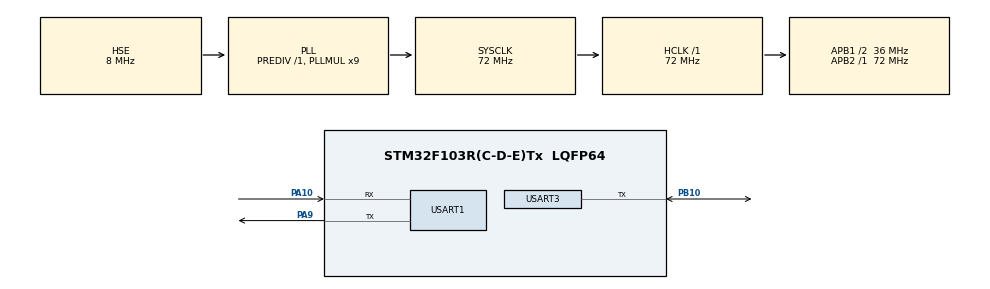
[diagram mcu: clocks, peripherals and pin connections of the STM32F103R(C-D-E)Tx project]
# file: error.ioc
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Mcu.Family=STM32F1
Mcu.Name=STM32F103R(C-D-E)Tx
Mcu.Package=LQFP64
NVIC.PriorityGroup=NVIC_PRIORITYGROUP_4
PA10.Mode=Asynchronous
PA10.Signal=USART1_RX
PA13.Mode=Serial_Wire
PA13.Signal=SYS_JTMS-SWDIO
PA14.Mode=Serial_Wire
PA14.Signal=SYS_JTCK-SWCLK
PA9.Mode=Asynchronous
PA9.Signal=USART1_TX
PB10.Mode=Half_duplex(single_wire_mode)
PB10.Signal=USART3_TX
PD0-OSC_IN.Mode=HSE-External-Oscillator
PD0-OSC_IN.Signal=RCC_OSC_IN
PD1-OSC_OUT.Mode=HSE-External-Oscillator
PD1-OSC_OUT.Signal=RCC_OSC_OUT
ProjectManager.HeapSize=0x200
ProjectManager.StackSize=0x400
ProjectManager.TargetToolchain=CMake
RCC.AHBFreq_Value=72000000
RCC.APB1CLKDivider=RCC_HCLK_DIV2
RCC.APB1Freq_Value=36000000
RCC.APB1TimFreq_Value=72000000
RCC.APB2Freq_Value=72000000
RCC.APB2TimFreq_Value=72000000
RCC.HCLKFreq_Value=72000000
RCC.PLLMUL=RCC_PLL_MUL9
RCC.PLLSourceVirtual=RCC_PLLSOURCE_HSE
RCC.SYSCLKFreq_VALUE=72000000
RCC.SYSCLKSource=RCC_SYSCLKSOURCE_PLLCLK
RCC.USBFreq_Value=72000000
USART1.VirtualMode=VM_ASYNC
USART3.VirtualMode=VM_ASYNC
board=custom

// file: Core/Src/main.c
/* USER CODE BEGIN Header */
/**
  ******************************************************************************
  * @file           : main.c
  * @brief          : Main program body
  ******************************************************************************
  * @attention
  *
  * Copyright (c) 2026 STMicroelectronics.
  * All rights reserved.
  *
  * This software is licensed under terms that can be found in the LICENSE file
  * in the root directory of this software component.
  * If no LICENSE file comes with this software, it is provided AS-IS.
  *
  ******************************************************************************
  */
/* USER CODE END Header */
#include "main.h"

/* USER CODE BEGIN Includes */
#include <stdio.h>          /* printf / getchar 的声明 */
#include "servo_app.h"      /* 舵机应用层：ServoApp_xxx */
/* USER CODE END Includes */

/* USER CODE BEGIN PD */
/* 演示开关：0 = 不动作，1 = 上电后每 2 秒在 45°/225° 之间来回 */
#define SERVO_DEMO_ENABLE 0
/* USER CODE END PD */

UART_HandleTypeDef huart1;
UART_HandleTypeDef huart3;

void SystemClock_Config(void);
static void MX_GPIO_Init(void);
static void MX_USART1_UART_Init(void);
static void MX_USART3_UART_Init(void);

/* USER CODE BEGIN 0 */
/*
 * printf 的底层出口。
 * newlib 的 printf 最终会调用 syscalls.c 里的 _write()，
 * 而 _write() 是 weak 的，它逐字节调用 __io_putchar()。
 * 这个函数不定义的话链接不报错，但运行时跳到 0 地址 -> HardFault。
 */
int __io_putchar(int ch)
{
  HAL_UART_Transmit(&huart1, (uint8_t *)&ch, 1U, 100U);
  return ch;
}

/* 同理，scanf / getchar 的入口；这里用不到，返回 -1 防止卡死 */
int __io_getchar(void)
{
  return -1;
}
/* USER CODE END 0 */

int main(void)
{

  /* MCU Configuration--------------------------------------------------------*/

  /* Reset of all peripherals, Initializes the Flash interface and the Systick. */
  HAL_Init();

  /* Configure the system clock */
  SystemClock_Config();

  /* Initialize all configured peripherals */
  MX_GPIO_Init();
  MX_USART1_UART_Init();
  MX_USART3_UART_Init();
  /* USER CODE BEGIN 2 */
  printf("\r\n==== bus servo init ====\r\n");

  ServoApp_Init(&huart3);                  /* 绑定串口，四颗摆到行程中点 */
  printf("init status : %d\r\n", (int)ServoApp_LastStatus());

  uint8_t mask = ServoApp_ScanPresent();   /* 0x0F = ID 1~4 都在线 */
  printf("present mask: 0x%02X\r\n", mask);
  /* USER CODE END 2 */

  /* Infinite loop */
  /* USER CODE BEGIN WHILE */
  uint32_t tick = HAL_GetTick();           /* 定时基准，只在进入循环前取一次 */

  while (1)
  {
    /* USER CODE END WHILE */

    /* USER CODE BEGIN 3 */
    /* 10ms 周期任务：tick 用累加而不是重新取时间，周期才不漂 */
    if ((HAL_GetTick() - tick) >= SERVO_TASK_PERIOD_MS)
    {
      tick += SERVO_TASK_PERIOD_MS;
      ServoApp_Task();
    }

#if SERVO_DEMO_ENABLE
    /* 演示：每 2 秒在 45° 和 225° 之间来回 */
    static uint32_t last_demo = 0;
    static int16_t  demo_deg  = 45;
    if ((HAL_GetTick() - last_demo) > 2000U)
    {
      last_demo = HAL_GetTick();
      ServoApp_SetAll((int16_t[]){demo_deg, demo_deg, demo_deg, demo_deg});
      demo_deg = (demo_deg == 45) ? 225 : 45;
    }
#endif
  }
  /* USER CODE END 3 */
}

void SystemClock_Config(void)
{
  RCC_OscInitTypeDef RCC_OscInitStruct = {0};
  RCC_ClkInitTypeDef RCC_ClkInitStruct = {0};

  /** Initializes the RCC Oscillators according to the specified parameters
  * in the RCC_OscInitTypeDef structure.
  */
  RCC_OscInitStruct.OscillatorType = RCC_OSCILLATORTYPE_HSE;
  RCC_OscInitStruct.HSEState = RCC_HSE_ON;
  RCC_OscInitStruct.HSEPredivValue = RCC_HSE_PREDIV_DIV1;
  RCC_OscInitStruct.HSIState = RCC_HSI_ON;
  RCC_OscInitStruct.PLL.PLLState = RCC_PLL_ON;
  RCC_OscInitStruct.PLL.PLLSource = RCC_PLLSOURCE_HSE;
  RCC_OscInitStruct.PLL.PLLMUL = RCC_PLL_MUL9;
  if (HAL_RCC_OscConfig(&RCC_OscInitStruct) != HAL_OK)
  {
    Error_Handler();
  }

  /** Initializes the CPU, AHB and APB buses clocks
  */
  RCC_ClkInitStruct.ClockType = RCC_CLOCKTYPE_HCLK|RCC_CLOCKTYPE_SYSCLK
                              |RCC_CLOCKTYPE_PCLK1|RCC_CLOCKTYPE_PCLK2;
  RCC_ClkInitStruct.SYSCLKSource = RCC_SYSCLKSOURCE_PLLCLK;
  RCC_ClkInitStruct.AHBCLKDivider = RCC_SYSCLK_DIV1;
  RCC_ClkInitStruct.APB1CLKDivider = RCC_HCLK_DIV2;
  RCC_ClkInitStruct.APB2CLKDivider = RCC_HCLK_DIV1;

  if (HAL_RCC_ClockConfig(&RCC_ClkInitStruct, FLASH_LATENCY_2) != HAL_OK)
  {
    Error_Handler();
  }
}

static void MX_USART1_UART_Init(void)
{

  huart1.Instance = USART1;
  huart1.Init.BaudRate = 115200;
  huart1.Init.WordLength = UART_WORDLENGTH_8B;
  huart1.Init.StopBits = UART_STOPBITS_1;
  huart1.Init.Parity = UART_PARITY_NONE;
  huart1.Init.Mode = UART_MODE_TX_RX;
  huart1.Init.HwFlowCtl = UART_HWCONTROL_NONE;
  huart1.Init.OverSampling = UART_OVERSAMPLING_16;
  if (HAL_UART_Init(&huart1) != HAL_OK)
  {
    Error_Handler();
  }

}

static void MX_USART3_UART_Init(void)
{

  huart3.Instance = USART3;
  huart3.Init.BaudRate = 115200;
  huart3.Init.WordLength = UART_WORDLENGTH_8B;
  huart3.Init.StopBits = UART_STOPBITS_1;
  huart3.Init.Parity = UART_PARITY_NONE;
  huart3.Init.Mode = UART_MODE_TX_RX;
  huart3.Init.HwFlowCtl = UART_HWCONTROL_NONE;
  huart3.Init.OverSampling = UART_OVERSAMPLING_16;
  if (HAL_HalfDuplex_Init(&huart3) != HAL_OK)
  {
    Error_Handler();
  }

}

static void MX_GPIO_Init(void)
{

  /* GPIO Ports Clock Enable */
  __HAL_RCC_GPIOD_CLK_ENABLE();
  __HAL_RCC_GPIOB_CLK_ENABLE();
  __HAL_RCC_GPIOA_CLK_ENABLE();

}

void Error_Handler(void)
{
  __disable_irq();
  while (1)
  {
  }
}
